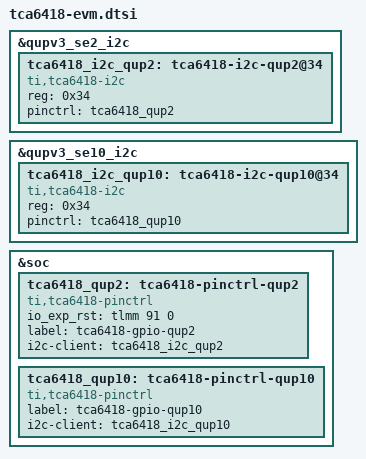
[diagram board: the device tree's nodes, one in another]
&qupv3_se2_i2c {
	status = "ok";
	tca6418_i2c_qup2: tca6418-i2c-qup2@34 {
		compatible = "ti,tca6418-i2c";
		reg = <0x34>;
		pinctrl = <&tca6418_qup2>;
	};
};

&qupv3_se10_i2c {
	status = "ok";
	tca6418_i2c_qup10: tca6418-i2c-qup10@34 {
		compatible = "ti,tca6418-i2c";
		reg = <0x34>;
		pinctrl = <&tca6418_qup10>;
	};
};

&soc {
	tca6418_qup2: tca6418-pinctrl-qup2 {
		compatible = "ti,tca6418-pinctrl";
		#gpio-cells = <2>;
		io_exp_rst = <&tlmm 91 0>;
		label = "tca6418-gpio-qup2";
		i2c-client = <&tca6418_i2c_qup2>;
	};
	tca6418_qup10: tca6418-pinctrl-qup10 {
		compatible = "ti,tca6418-pinctrl";
		#gpio-cells = <2>;
		label = "tca6418-gpio-qup10";
		i2c-client = <&tca6418_i2c_qup10>;
	};
};
